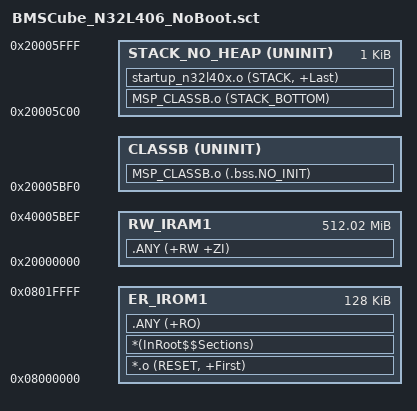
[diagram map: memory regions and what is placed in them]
; ****************************************************************
; Scatter-Loading Description File for IEC 60335 compliant project
; ****************************************************************
; WARNING: Class B variables and their inverse redundant parts
; must be manually placed using the __at attributes in the 
; n32g0xx_SelfTest_classBvar.h file.
; The start address of CLASSB, CLASSB_INV and RW_IRAM1 region 
; must be manually modified to be in-line with this file.

  LR_IROM1 0x08000000 0x00020000  {    ; load region size_region
    ER_IROM1 0x08000000 0x00020000  {  ; load address = execution address
      *.o (RESET, +First)
      *(InRoot$$Sections)
      .ANY (+RO)
    }

    RW_IRAM1 0x20000000 0x20005BF0
    {     ; RW data (Class A variables)
      .ANY (+RW +ZI)
    }

    CLASSB 0x20005BF0 UNINIT
    {		        ; Class B variables
		MSP_CLASSB.o (.bss.NO_INIT)
    }
    
    STACK_NO_HEAP 0x20005C00 UNINIT 0x400  { ; Stack and magic pattern for stack overflow detection
   	  MSP_CLASSB.o (STACK_BOTTOM)
	  startup_n32l40x.o (STACK, +Last)
    }
	
  }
